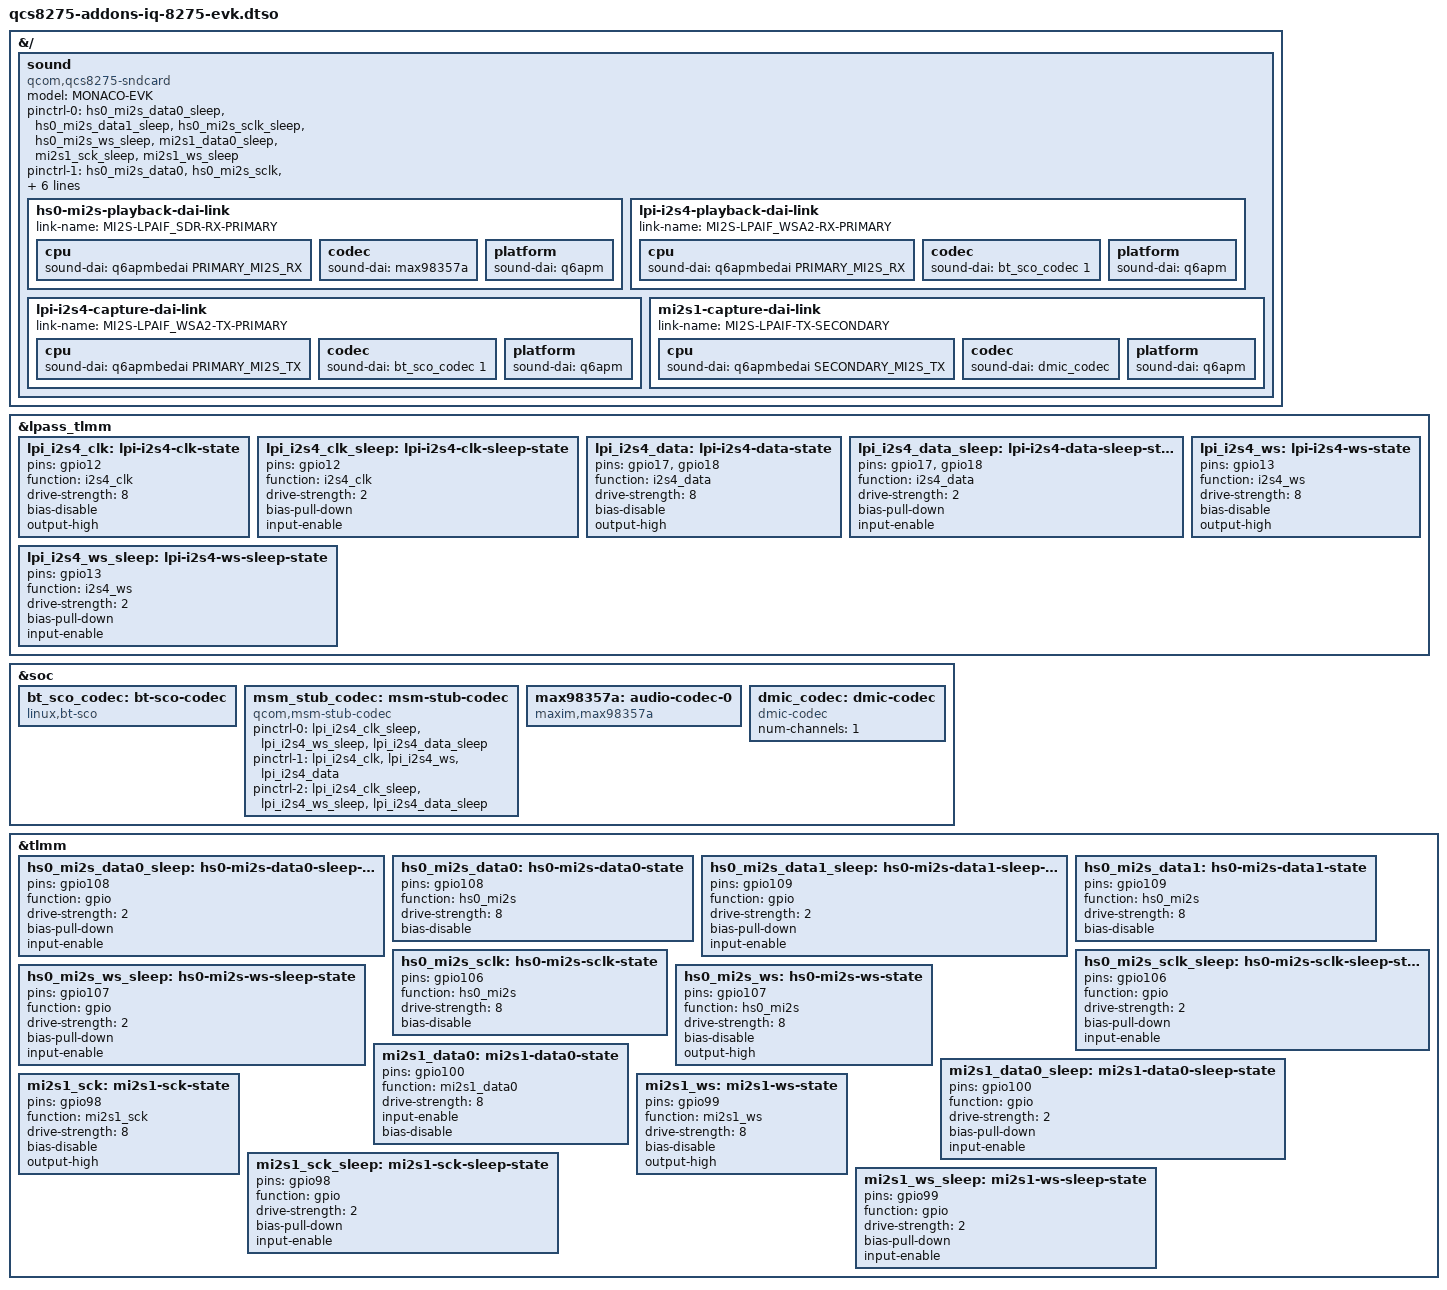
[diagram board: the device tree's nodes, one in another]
// SPDX-License-Identifier: BSD-3-Clause
/*
 * Copyright (c) Qualcomm Technologies, Inc. and/or its subsidiaries.
 */

/dts-v1/;
/plugin/;

#include "qcs8300-addons.dtsi"
#include "qcs8275-thermal-addons.dtsi"

&{/} {
	sound {
		compatible = "qcom,qcs8275-sndcard";
		model = "MONACO-EVK";

		pinctrl-0 = <&hs0_mi2s_data0_sleep>,<&hs0_mi2s_data1_sleep>,<&hs0_mi2s_sclk_sleep>,
			    <&hs0_mi2s_ws_sleep>,<&mi2s1_data0_sleep>,<&mi2s1_sck_sleep>,
			    <&mi2s1_ws_sleep>;
		pinctrl-1 = <&hs0_mi2s_data0>, <&hs0_mi2s_sclk>, <&hs0_mi2s_data1>,
			    <&hs0_mi2s_ws>, <&mi2s1_data0>, <&mi2s1_sck>, <&mi2s1_ws>;
		pinctrl-2 = <&hs0_mi2s_data0_sleep>,<&hs0_mi2s_data1_sleep>,<&hs0_mi2s_sclk_sleep>,
			    <&hs0_mi2s_ws_sleep>,<&mi2s1_data0_sleep>,<&mi2s1_sck_sleep>,
			    <&mi2s1_ws_sleep>;
		pinctrl-names = "default", "mi2s_active", "mi2s_sleep";

		hs0-mi2s-playback-dai-link {
			link-name = "MI2S-LPAIF_SDR-RX-PRIMARY";

			cpu {
				sound-dai = <&q6apmbedai PRIMARY_MI2S_RX>;
			};

			codec {
				sound-dai = <&max98357a>;
			};

			platform {
				sound-dai = <&q6apm>;
			};
		};

		lpi-i2s4-playback-dai-link {
			link-name = "MI2S-LPAIF_WSA2-RX-PRIMARY";

			cpu {
				sound-dai = <&q6apmbedai PRIMARY_MI2S_RX>;
			};

			codec {
				sound-dai = <&bt_sco_codec 1>;
			};

			platform {
				sound-dai = <&q6apm>;
			};
		};

		lpi-i2s4-capture-dai-link {
			link-name = "MI2S-LPAIF_WSA2-TX-PRIMARY";

			cpu {
				sound-dai = <&q6apmbedai PRIMARY_MI2S_TX>;
			};

			codec {
				sound-dai = <&bt_sco_codec 1>;
			};

			platform {
				sound-dai = <&q6apm>;
			};
		};

		mi2s1-capture-dai-link {
			link-name = "MI2S-LPAIF-TX-SECONDARY";

			cpu {
				sound-dai = <&q6apmbedai SECONDARY_MI2S_TX>;
			};

			codec {
				sound-dai = <&dmic_codec>;
			};

			platform {
				sound-dai = <&q6apm>;
			};
		};


	};
};

&lpass_tlmm {

	lpi_i2s4_clk: lpi-i2s4-clk-state {
		pins = "gpio12";
		function = "i2s4_clk";
		drive-strength = <8>;
		bias-disable;
		output-high;
	};

	lpi_i2s4_clk_sleep: lpi-i2s4-clk-sleep-state {
		pins = "gpio12";
		function = "i2s4_clk";
		drive-strength = <2>;
		bias-pull-down;
		input-enable;
	};

	lpi_i2s4_data: lpi-i2s4-data-state {
		pins = "gpio17", "gpio18";
		function = "i2s4_data";
		drive-strength = <8>;
		bias-disable;
		output-high;
	};

	lpi_i2s4_data_sleep: lpi-i2s4-data-sleep-state {
		pins = "gpio17", "gpio18";
		function = "i2s4_data";
		drive-strength = <2>;
		bias-pull-down;
		input-enable;
	};

	lpi_i2s4_ws: lpi-i2s4-ws-state {
		pins = "gpio13";
		function = "i2s4_ws";
		drive-strength = <8>;
		bias-disable;
		output-high;
	};

	lpi_i2s4_ws_sleep: lpi-i2s4-ws-sleep-state {
		pins = "gpio13";
		function = "i2s4_ws";
		drive-strength = <2>;
		bias-pull-down;
		input-enable;
	};

};

&soc {

	bt_sco_codec: bt-sco-codec {
		#sound-dai-cells = <1>;
		compatible = "linux,bt-sco";
	};

	msm_stub_codec: msm-stub-codec {
		compatible = "qcom,msm-stub-codec";

		pinctrl-0 = <&lpi_i2s4_clk_sleep>, <&lpi_i2s4_ws_sleep>, <&lpi_i2s4_data_sleep>;
		pinctrl-1 = <&lpi_i2s4_clk>, <&lpi_i2s4_ws>, <&lpi_i2s4_data>;
		pinctrl-2 = <&lpi_i2s4_clk_sleep>, <&lpi_i2s4_ws_sleep>, <&lpi_i2s4_data_sleep>;
		pinctrl-names = "default", "mi2s_aud_active", "mi2s_aud_sleep";

		#sound-dai-cells = <1>;
	};

	max98357a: audio-codec-0 {
		compatible = "maxim,max98357a";
		#sound-dai-cells = <0>;
	};

	dmic_codec: dmic-codec {
		compatible = "dmic-codec";
		#sound-dai-cells = <0>;
		num-channels = <1>;
	};

};

&tlmm {
	hs0_mi2s_data0_sleep: hs0-mi2s-data0-sleep-state {
		pins = "gpio108";
		function = "gpio";
		drive-strength = <2>;
		bias-pull-down;
		input-enable;
	};

	hs0_mi2s_data0: hs0-mi2s-data0-state {
		pins = "gpio108";
		function = "hs0_mi2s";
		drive-strength = <8>;
		bias-disable;
	};

	hs0_mi2s_data1_sleep: hs0-mi2s-data1-sleep-state {
		pins = "gpio109";
		function = "gpio";
		drive-strength = <2>;
		bias-pull-down;
		input-enable;
	};

	hs0_mi2s_data1: hs0-mi2s-data1-state {
		pins = "gpio109";
		function = "hs0_mi2s";
		drive-strength = <8>;
		bias-disable;
	};

	hs0_mi2s_sclk_sleep: hs0-mi2s-sclk-sleep-state {
		pins = "gpio106";
		function = "gpio";
		drive-strength = <2>;
		bias-pull-down;
		input-enable;
	};

	hs0_mi2s_sclk: hs0-mi2s-sclk-state {
		pins = "gpio106";
		function = "hs0_mi2s";
		drive-strength = <8>;
		bias-disable;
	};

	hs0_mi2s_ws_sleep: hs0-mi2s-ws-sleep-state {
		pins = "gpio107";
		function = "gpio";
		drive-strength = <2>;
		bias-pull-down;
		input-enable;
	};

	hs0_mi2s_ws: hs0-mi2s-ws-state {
		pins = "gpio107";
		function = "hs0_mi2s";
		drive-strength = <8>;
		bias-disable;
		output-high;
	};

	mi2s1_data0: mi2s1-data0-state {
		pins = "gpio100";
		function = "mi2s1_data0";
		drive-strength = <8>;
		input-enable;
		bias-disable;
	};

	mi2s1_data0_sleep: mi2s1-data0-sleep-state {
		pins = "gpio100";
		function = "gpio";
		drive-strength = <2>;
		bias-pull-down;
		input-enable;
	};

	mi2s1_sck: mi2s1-sck-state {
		pins = "gpio98";
		function = "mi2s1_sck";
		drive-strength = <8>;
		bias-disable;
		output-high;
	};

	mi2s1_sck_sleep: mi2s1-sck-sleep-state {
		pins = "gpio98";
		function = "gpio";
		drive-strength = <2>;
		bias-pull-down;
		input-enable;
	};

	mi2s1_ws: mi2s1-ws-state {
		pins = "gpio99";
		function = "mi2s1_ws";
		drive-strength = <8>;
		bias-disable;
		output-high;
	};

	mi2s1_ws_sleep: mi2s1-ws-sleep-state {
		pins = "gpio99";
		function = "gpio";
		drive-strength = <2>;
		bias-pull-down;
		input-enable;
	};

};

